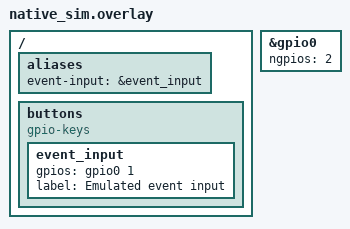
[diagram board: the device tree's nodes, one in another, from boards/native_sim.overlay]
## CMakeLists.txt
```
cmake_minimum_required(VERSION 3.20.0)
find_package(Zephyr REQUIRED HINTS $ENV{ZEPHYR_BASE})
project(day3_shell_stimulus)
target_include_directories(app PRIVATE include)
target_sources(app PRIVATE src/main.c src/event_service.c src/stimulus.c src/event_shell.c
			   src/event_channels.c src/stimulus_subscriber.c
			   src/event_input_listener.c)
```

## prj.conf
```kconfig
CONFIG_PRINTK=y
CONFIG_LOG=y
CONFIG_LOG_MODE_IMMEDIATE=y
CONFIG_LOG_DEFAULT_LEVEL=3
CONFIG_LOG_MAX_LEVEL=4
CONFIG_GPIO=y
CONFIG_SHELL=y
CONFIG_SHELL_BACKEND_SERIAL=y
CONFIG_MAIN_STACK_SIZE=2048
CONFIG_SYSTEM_WORKQUEUE_STACK_SIZE=2048
CONFIG_ZBUS=y
CONFIG_ZBUS_MSG_SUBSCRIBER=y
CONFIG_ZBUS_ASYNC_LISTENER=y
CONFIG_HEAP_MEM_POOL_SIZE=1024
CONFIG_ZBUS_MSG_SUBSCRIBER_NET_BUF_POOL_SIZE=32

# TODO: Add any additional options required by your stimulus implementation.
```

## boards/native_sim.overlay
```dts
/ {
	aliases {
		event-input = &event_input;
	};

	buttons {
		compatible = "gpio-keys";

		event_input: event_input {
			gpios = <&gpio0 1 GPIO_ACTIVE_HIGH>;
			label = "Emulated event input";
		};
	};
};

&gpio0 {
	ngpios = <2>;
};
```

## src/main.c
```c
#include <errno.h>
#include <zephyr/drivers/gpio.h>
#include <zephyr/logging/log.h>

#include "event_channels.h"
#include "event_service.h"
#include "stimulus.h"

LOG_MODULE_REGISTER(day3_shell_stimulus, LOG_LEVEL_INF);

static const struct gpio_dt_spec input =
	GPIO_DT_SPEC_GET(DT_ALIAS(event_input), gpios);
static struct gpio_callback input_callback;
static uint32_t input_sequence;

static void input_changed(const struct device *port, struct gpio_callback *callback,
			  gpio_port_pins_t pins)
{
	ARG_UNUSED(port);
	ARG_UNUSED(callback);
	if ((pins & BIT(input.pin)) != 0U) {
		int active = gpio_pin_get_dt(&input);

		if (active <= 0) {
			return;
		}
		/* TODO: Publish an active-edge input event without blocking this callback. */
		struct event_input event = {
			.source = EVENT_SOURCE_EMULATED,
			.sequence = ++input_sequence,
			.active = true,
			.timestamp = k_uptime_get(),
		};
		int ret = zbus_chan_pub(&event_input_chan, &event, K_NO_WAIT);

		if (ret == 0) {
			event_service_record_input_published();
		} else {
			event_service_record_publish_failure(ret);
			LOG_ERR("input publish failed: %d", ret);
		}
	}
}

int main(void)
{
	int ret = event_service_init();

	if (ret != 0) {
		LOG_ERR("Event service initialization failed: %d", ret);
		return ret;
	}
	if (!gpio_is_ready_dt(&input)) {
		LOG_ERR("Event input device is not ready");
		return -ENODEV;
	}
	ret = gpio_pin_configure_dt(&input, GPIO_INPUT);
	if (ret != 0) {
		LOG_ERR("Cannot configure event input: %d", ret);
		return ret;
	}
	gpio_init_callback(&input_callback, input_changed, BIT(input.pin));
	ret = gpio_add_callback(input.port, &input_callback);
	if (ret != 0) {
		LOG_ERR("Cannot add GPIO callback: %d", ret);
		return ret;
	}
	ret = stimulus_init(&input);
	if (ret != 0) {
		LOG_ERR("Cannot initialize stimulus: %d", ret);
		return ret;
	}
	ret = gpio_pin_interrupt_configure_dt(&input, GPIO_INT_EDGE_BOTH);
	if (ret != 0) {
		LOG_ERR("Cannot enable GPIO edges: %d", ret);
		return ret;
	}
	LOG_INF("Try: event status, event stats, event input 1, event pulse, event burst 3 200");
	return 0;
}
```

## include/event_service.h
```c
#ifndef EVENT_SERVICE_H
#define EVENT_SERVICE_H

#include <stdint.h>

struct event_stats {
	uint32_t raw_count;
	uint32_t processed_count;
};

int event_service_init(void);
void event_service_record_raw(void);
void event_service_get_stats(struct event_stats *stats);
void event_service_reset_stats(void);

#endif
```

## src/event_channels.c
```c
#include "event_channels.h"

/* TODO: Bind the command subscriber and input listener to their channels. */
ZBUS_CHAN_DEFINE(event_cmd_chan, struct event_command, NULL, NULL,
		 ZBUS_OBSERVERS_EMPTY,
		 ZBUS_MSG_INIT(.type = EVENT_CMD_RESET));
ZBUS_CHAN_DEFINE(event_input_chan, struct event_input, NULL, NULL,
		 ZBUS_OBSERVERS_EMPTY,
		 ZBUS_MSG_INIT(.source = EVENT_SOURCE_EMULATED));
```

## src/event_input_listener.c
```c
#include <zephyr/logging/log.h>

#include "event_channels.h"
#include "event_service.h"

LOG_MODULE_REGISTER(event_input_listener, LOG_LEVEL_INF);

static void input_callback(const struct zbus_channel *chan, const void *message)
{
	/* TODO: Validate and account for the received event in this async context. */
	ARG_UNUSED(chan);
	ARG_UNUSED(message);
}

ZBUS_ASYNC_LISTENER_DEFINE(event_input_listener, input_callback);
```

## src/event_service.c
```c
#include <errno.h>
#include <zephyr/kernel.h>
#include <zephyr/sys/atomic.h>

#include "event_service.h"

static atomic_t cmd_published;
static atomic_t cmd_received;
static atomic_t cmd_rejected;
static atomic_t input_published;
static atomic_t input_received;
static atomic_t processed;
static atomic_t publish_failed;
static atomic_t last_error;
K_SEM_DEFINE(event_pending, 0, UINT_MAX);

static void event_worker(void *p1, void *p2, void *p3)
{
	ARG_UNUSED(p1);
	ARG_UNUSED(p2);
	ARG_UNUSED(p3);
	while (true) {
		k_sem_take(&event_pending, K_FOREVER);
		/* TODO: Perform the application work before incrementing processed. */
	}
}

K_THREAD_DEFINE(event_worker_thread, 1024, event_worker, NULL, NULL, NULL,
		K_PRIO_PREEMPT(3), 0, 0);

int event_service_init(void)
{
	/* TODO: Reset the complete stable statistics set. */
	return 0;
}

void event_service_record_command_published(void) { atomic_inc(&cmd_published); }
void event_service_record_command_received(void) { atomic_inc(&cmd_received); }

void event_service_reject(int error)
{
	atomic_inc(&cmd_rejected);
	atomic_set(&last_error, error);
}

void event_service_record_input_published(void) { atomic_inc(&input_published); }

void event_service_record_input_received(void)
{
	atomic_inc(&input_received);
	k_sem_give(&event_pending);
}

void event_service_record_publish_failure(int error)
{
	atomic_inc(&publish_failed);
	atomic_set(&last_error, error);
}

int event_service_get_stats(struct event_stats *stats)
{
	if (stats == NULL) {
		return -EINVAL;
	}
	stats->cmd_published = (uint32_t)atomic_get(&cmd_published);
	stats->cmd_received = (uint32_t)atomic_get(&cmd_received);
	stats->cmd_rejected = (uint32_t)atomic_get(&cmd_rejected);
	stats->input_published = (uint32_t)atomic_get(&input_published);
	stats->input_received = (uint32_t)atomic_get(&input_received);
	stats->processed = (uint32_t)atomic_get(&processed);
	stats->publish_failed = (uint32_t)atomic_get(&publish_failed);
	stats->last_error = (int32_t)atomic_get(&last_error);
	return 0;
}

int event_service_reset_stats(void)
{
	/* TODO: Reset all counters while leaving the active stimulus untouched. */
	return -ENOSYS;
}
```

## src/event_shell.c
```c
#include <errno.h>
#include <stdlib.h>
#include <zephyr/shell/shell.h>

#include "event_channels.h"
#include "event_service.h"
#include "stimulus.h"

static int parse_u32(const struct shell *sh, const char *text, uint32_t min,
		     uint32_t max, uint32_t *value)
{
	char *end;
	unsigned long parsed;

	if (text == NULL || text[0] == '\0') {
		event_service_reject(-EINVAL);
		shell_error(sh, "expected an unsigned integer");
		return -EINVAL;
	}
	for (const char *digit = text; *digit != '\0'; digit++) {
		if (*digit < '0' || *digit > '9') {
			event_service_reject(-EINVAL);
			shell_error(sh, "expected an unsigned integer");
			return -EINVAL;
		}
	}
	errno = 0;
	parsed = strtoul(text, &end, 10);
	if (errno != 0 || end == text || *end != '\0' || parsed < min || parsed > max) {
		event_service_reject(-ERANGE);
		shell_error(sh, "value must be in range %u..%u", min, max);
		return -ERANGE;
	}
	*value = (uint32_t)parsed;
	return 0;
}

static int publish_command(const struct shell *sh, struct event_command *command)
{
	ARG_UNUSED(command);
	/* TODO: Publish to event_cmd_chan and surface the return code. */
	shell_error(sh, "command publisher is not implemented yet");
	return -ENOSYS;
}

static int cmd_status(const struct shell *sh, size_t argc, char **argv)
{
	struct stimulus_status status;

	ARG_UNUSED(argc);
	ARG_UNUSED(argv);
	stimulus_get_status(&status);
	shell_print(sh, "input=%s stimulus=%s remaining=%u last_error=%d",
		    status.input_active ? "active" : "idle", status.mode,
		    status.remaining, status.last_error);
	return 0;
}

static int cmd_stats(const struct shell *sh, size_t argc, char **argv)
{
	struct event_stats stats;
	int ret;

	ARG_UNUSED(argc);
	ARG_UNUSED(argv);
	ret = event_service_get_stats(&stats);
	if (ret != 0) {
		shell_error(sh, "stats unavailable: %d", ret);
		return ret;
	}
	shell_print(sh, "cmd_published=%u cmd_received=%u cmd_rejected=%u input_published=%u input_received=%u processed=%u publish_failed=%u last_error=%d",
		    stats.cmd_published, stats.cmd_received, stats.cmd_rejected,
		    stats.input_published, stats.input_received, stats.processed,
		    stats.publish_failed, stats.last_error);
	return 0;
}

static int cmd_reset(const struct shell *sh, size_t argc, char **argv)
{
	struct event_command command = {.type = EVENT_CMD_RESET};

	ARG_UNUSED(argc);
	ARG_UNUSED(argv);
	return publish_command(sh, &command);
}

static int cmd_input(const struct shell *sh, size_t argc, char **argv)
{
	struct event_command command = {.type = EVENT_CMD_INPUT};
	uint32_t value;
	int ret;

	ARG_UNUSED(argc);
	ret = parse_u32(sh, argv[1], 0U, 1U, &value);
	if (ret != 0) {
		return ret;
	}
	command.value = (int32_t)value;
	return publish_command(sh, &command);
}

static int cmd_pulse(const struct shell *sh, size_t argc, char **argv)
{
	struct event_command command = {.type = EVENT_CMD_PULSE, .duration_ms = 100U};
	int ret = 0;

	if (argc > 1U) {
		ret = parse_u32(sh, argv[1], 20U, 2000U, &command.duration_ms);
	}
	return ret != 0 ? ret : publish_command(sh, &command);
}

static int cmd_burst(const struct shell *sh, size_t argc, char **argv)
{
	struct event_command command = {.type = EVENT_CMD_BURST};
	int ret;

	ARG_UNUSED(argc);
	ret = parse_u32(sh, argv[1], 1U, 20U, &command.count);
	if (ret == 0) {
		ret = parse_u32(sh, argv[2], 20U, 2000U, &command.interval_ms);
	}
	return ret != 0 ? ret : publish_command(sh, &command);
}

static int cmd_cancel(const struct shell *sh, size_t argc, char **argv)
{
	struct event_command command = {.type = EVENT_CMD_CANCEL};

	ARG_UNUSED(argc);
	ARG_UNUSED(argv);
	return publish_command(sh, &command);
}

SHELL_STATIC_SUBCMD_SET_CREATE(event_commands,
	SHELL_CMD_ARG(status, NULL, "Show event and stimulus status", cmd_status, 1, 0),
	SHELL_CMD_ARG(stats, NULL, "Show input event counters", cmd_stats, 1, 0),
	SHELL_CMD_ARG(reset, NULL, "Publish statistics reset", cmd_reset, 1, 0),
	SHELL_CMD_ARG(input, NULL, "Set emulated input: 0 or 1", cmd_input, 2, 0),
	SHELL_CMD_ARG(pulse, NULL, "Generate pulse: optional duration_ms", cmd_pulse, 1, 2),
	SHELL_CMD_ARG(burst, NULL, "Generate pulses: count and gap_ms", cmd_burst, 3, 0),
	SHELL_CMD_ARG(cancel, NULL, "Cancel active stimulus", cmd_cancel, 1, 0),
	SHELL_SUBCMD_SET_END
);
SHELL_CMD_REGISTER(event, &event_commands, "Event stimulus command publisher", NULL);
```

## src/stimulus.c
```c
#include <errno.h>
#include <zephyr/kernel.h>

#include "stimulus.h"

static struct stimulus_status current_status = {
	.mode = "idle",
	.last_error = -ENOSYS,
};

int stimulus_init(const struct gpio_dt_spec *input)
{
	if (input == NULL || !gpio_is_ready_dt(input)) {
		return -ENODEV;
	}
	/* TODO: Store the GPIO spec and configure a known inactive emulator level. */
	current_status = (struct stimulus_status){
		.input_active = false,
		.mode = "idle",
		.remaining = 0U,
		.last_error = -ENOSYS,
	};
	return 0;
}

int stimulus_set_input(bool active)
{
	/* TODO: Set the emulated GPIO level; reject manual changes while busy. */
	ARG_UNUSED(active);
	return -ENOSYS;
}

int stimulus_start_pulse(uint32_t duration_ms)
{
	/* TODO: Validate duration and schedule an active/inactive pulse without blocking. */
	ARG_UNUSED(duration_ms);
	return -ENOSYS;
}

int stimulus_start_burst(uint32_t count, uint32_t gap_ms)
{
	/* TODO: Schedule exactly count pulses and reject overlapping sequences. */
	ARG_UNUSED(count);
	ARG_UNUSED(gap_ms);
	return -ENOSYS;
}

int stimulus_cancel(void)
{
	/* TODO: Cancel scheduled work and guarantee the inactive end level. */
	return -ENOSYS;
}

void stimulus_get_status(struct stimulus_status *status)
{
	if (status != NULL) {
		/* TODO: Return a synchronized snapshot of the stimulus state. */
		*status = current_status;
	}
}
```

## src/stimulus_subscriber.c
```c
#include <zephyr/kernel.h>
#include <zephyr/logging/log.h>

#include "event_channels.h"
#include "event_service.h"

LOG_MODULE_REGISTER(stimulus_subscriber, LOG_LEVEL_INF);

ZBUS_MSG_SUBSCRIBER_DEFINE(event_stimulus_subscriber);

static void subscriber_thread(void *p1, void *p2, void *p3)
{
	const struct zbus_channel *chan;
	struct event_command command;

	ARG_UNUSED(p1);
	ARG_UNUSED(p2);
	ARG_UNUSED(p3);
	while (zbus_sub_wait_msg(&event_stimulus_subscriber, &chan, &command, K_FOREVER) == 0) {
		/* TODO: Route the command to the stimulus adapter, not directly from the shell. */
		if (chan == &event_cmd_chan) {
			event_service_record_command_received();
			LOG_INF("received stimulus command type=%d", command.type);
		}
	}
}

K_THREAD_DEFINE(event_stimulus_subscriber_thread, 1536, subscriber_thread,
		NULL, NULL, NULL, K_PRIO_PREEMPT(3), 0, 0);
```
